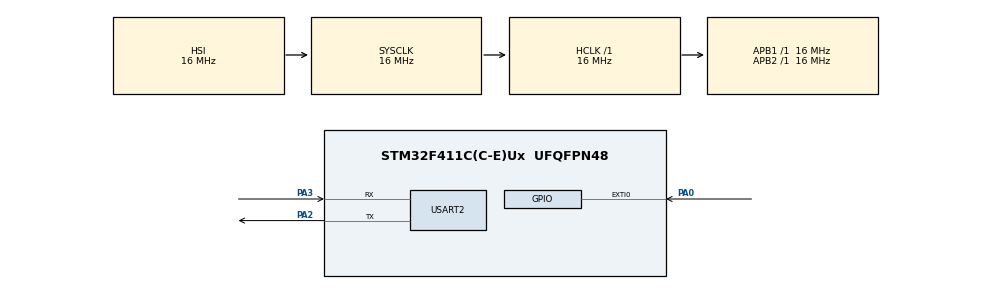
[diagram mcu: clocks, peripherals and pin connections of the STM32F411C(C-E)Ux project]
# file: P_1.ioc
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Mcu.Family=STM32F4
Mcu.Name=STM32F411C(C-E)Ux
Mcu.Package=UFQFPN48
NVIC.EXTI0_IRQn=true\:0\:0\:false\:false\:true\:true\:true\:true
NVIC.PriorityGroup=NVIC_PRIORITYGROUP_4
PA0-WKUP.GPIO_PuPd=GPIO_PULLUP
PA0-WKUP.Signal=GPXTI0
PA2.Mode=Asynchronous
PA2.Signal=USART2_TX
PA3.Mode=Asynchronous
PA3.Signal=USART2_RX
ProjectManager.HeapSize=0x200
ProjectManager.StackSize=0x400
ProjectManager.TargetToolchain=STM32CubeIDE
RCC.48MHZClocksFreq_Value=48000000
RCC.AHBFreq_Value=16000000
RCC.APB1Freq_Value=16000000
RCC.APB1TimFreq_Value=16000000
RCC.APB2Freq_Value=16000000
RCC.APB2TimFreq_Value=16000000
RCC.CortexFreq_Value=16000000
RCC.HCLKFreq_Value=16000000
RCC.HSE_VALUE=25000000
RCC.HSI_VALUE=16000000
RCC.LSE_VALUE=32768
RCC.PLLP=RCC_PLLP_DIV4
RCC.SYSCLKFreq_VALUE=16000000
RCC.VCOOutputFreq_Value=192000000
USART2.VirtualMode=VM_ASYNC
VP_CRC_VS_CRC.Mode=CRC_Activate
board=custom

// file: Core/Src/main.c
/* USER CODE BEGIN Header */
/**
  ******************************************************************************
  * @file           : main.c
  * @brief          : Main program body
  ******************************************************************************
  * @attention
  *
  * Copyright (c) 2025 STMicroelectronics.
  * All rights reserved.
  *
  * This software is licensed under terms that can be found in the LICENSE file
  * in the root directory of this software component.
  * If no LICENSE file comes with this software, it is provided AS-IS.
  *
  ******************************************************************************
  */
/* USER CODE END Header */
#include "main.h"

/* USER CODE BEGIN Includes */
#include <string.h>
#include <stdarg.h>
#include <stdio.h>
/* USER CODE END Includes */

CRC_HandleTypeDef hcrc;

UART_HandleTypeDef huart2;

/* USER CODE BEGIN PV */
#define C_UART			huart2

uint8_t bl_rx_buffer[200];
/* USER CODE END PV */

void SystemClock_Config(void);
static void MX_GPIO_Init(void);
static void MX_CRC_Init(void);
static void MX_USART2_UART_Init(void);
/* USER CODE BEGIN PFP */
static void printmsg(char *format,...);
static void bootloader_send_ack(uint8_t command_code, uint8_t follow_len);
static void bootloader_send_nack(void);
uint8_t bootloader_verify_crc (uint8_t *pData, uint32_t len, uint32_t crc_host);
static uint8_t get_bootloader_version(void);
static void bootloader_uart_write_data(uint8_t *pBuffer,uint32_t len);

/* USER CODE END PFP */

int main(void)
{

  /* USER CODE BEGIN 1 */
#define BL_DEBUG_MSG_EN		1
  /* USER CODE END 1 */

  /* MCU Configuration--------------------------------------------------------*/

  /* Reset of all peripherals, Initializes the Flash interface and the Systick. */
  HAL_Init();

  /* Configure the system clock */
  SystemClock_Config();

  /* Initialize all configured peripherals */
  MX_GPIO_Init();
  MX_CRC_Init();
  MX_USART2_UART_Init();
  /* USER CODE BEGIN 2 */

  if(HAL_GPIO_ReadPin(GPIOA, GPIO_PIN_0) == 0)
  {
	  // button is pressed
	  printmsg("BL_DEBUG_MSG:Button is pressed .. going to BL mode \r\n");

	  bootloader_uart_read_data();
  }
  else
  {
	printmsg("BL_DEBUG_MSG:Button is not pressed .. executing user app\r\n");
	 bootloader_jump_to_user_app();
  }

  /* USER CODE END 2 */

  /* Infinite loop */
  while (1)
  {

  }
}

void SystemClock_Config(void)
{
  RCC_OscInitTypeDef RCC_OscInitStruct = {0};
  RCC_ClkInitTypeDef RCC_ClkInitStruct = {0};

  /** Configure the main internal regulator output voltage
  */
  __HAL_RCC_PWR_CLK_ENABLE();
  __HAL_PWR_VOLTAGESCALING_CONFIG(PWR_REGULATOR_VOLTAGE_SCALE1);

  /** Initializes the RCC Oscillators according to the specified parameters
  * in the RCC_OscInitTypeDef structure.
  */
  RCC_OscInitStruct.OscillatorType = RCC_OSCILLATORTYPE_HSI;
  RCC_OscInitStruct.HSIState = RCC_HSI_ON;
  RCC_OscInitStruct.HSICalibrationValue = RCC_HSICALIBRATION_DEFAULT;
  RCC_OscInitStruct.PLL.PLLState = RCC_PLL_NONE;
  if (HAL_RCC_OscConfig(&RCC_OscInitStruct) != HAL_OK)
  {
    Error_Handler();
  }

  /** Initializes the CPU, AHB and APB buses clocks
  */
  RCC_ClkInitStruct.ClockType = RCC_CLOCKTYPE_HCLK|RCC_CLOCKTYPE_SYSCLK
                              |RCC_CLOCKTYPE_PCLK1|RCC_CLOCKTYPE_PCLK2;
  RCC_ClkInitStruct.SYSCLKSource = RCC_SYSCLKSOURCE_HSI;
  RCC_ClkInitStruct.AHBCLKDivider = RCC_SYSCLK_DIV1;
  RCC_ClkInitStruct.APB1CLKDivider = RCC_HCLK_DIV1;
  RCC_ClkInitStruct.APB2CLKDivider = RCC_HCLK_DIV1;

  if (HAL_RCC_ClockConfig(&RCC_ClkInitStruct, FLASH_LATENCY_0) != HAL_OK)
  {
    Error_Handler();
  }
}

static void MX_CRC_Init(void)
{

  hcrc.Instance = CRC;
  if (HAL_CRC_Init(&hcrc) != HAL_OK)
  {
    Error_Handler();
  }

}

static void MX_USART2_UART_Init(void)
{

  huart2.Instance = USART2;
  huart2.Init.BaudRate = 9600;
  huart2.Init.WordLength = UART_WORDLENGTH_8B;
  huart2.Init.StopBits = UART_STOPBITS_1;
  huart2.Init.Parity = UART_PARITY_NONE;
  huart2.Init.Mode = UART_MODE_TX_RX;
  huart2.Init.HwFlowCtl = UART_HWCONTROL_NONE;
  huart2.Init.OverSampling = UART_OVERSAMPLING_16;
  if (HAL_UART_Init(&huart2) != HAL_OK)
  {
    Error_Handler();
  }

}

static void MX_GPIO_Init(void)
{
  GPIO_InitTypeDef GPIO_InitStruct = {0};

  /* GPIO Ports Clock Enable */
  __HAL_RCC_GPIOA_CLK_ENABLE();

  /*Configure GPIO pin : PA0 */
  GPIO_InitStruct.Pin = GPIO_PIN_0;
  GPIO_InitStruct.Mode = GPIO_MODE_IT_RISING;
  GPIO_InitStruct.Pull = GPIO_PULLUP;
  HAL_GPIO_Init(GPIOA, &GPIO_InitStruct);

  /* EXTI interrupt init*/
  HAL_NVIC_SetPriority(EXTI0_IRQn, 0, 0);
  HAL_NVIC_EnableIRQ(EXTI0_IRQn);

}

/* USER CODE BEGIN 4 */
static void printmsg(char *format,...)
{
#ifdef BL_DEBUG_MSG_EN
	char str[80];

	va_list args;
	va_start(args, format);
	vsprintf(str, format, args);
	HAL_UART_Transmit(&huart2, (uint8_t*)str, strlen(str), HAL_MAX_DELAY);
	va_end(args);
#endif
}

void bootloader_uart_read_data(void)
{
	uint8_t rcv_len;
	memset(bl_rx_buffer, 0, 200);

	HAL_UART_Receive(&C_UART, bl_rx_buffer, 1, HAL_MAX_DELAY);
	rcv_len = bl_rx_buffer[0];
	HAL_UART_Receive(&C_UART, &bl_rx_buffer[1], rcv_len, HAL_MAX_DELAY);
	switch(bl_rx_buffer[1])
	{
		 case BL_GET_VER:
	          bootloader_handle_getver_cmd(bl_rx_buffer);
	          break;
	      case BL_GET_HELP:
	          bootloader_handle_gethelp_cmd(bl_rx_buffer);
	          break;
	      case BL_GET_CID:
	          bootloader_handle_getcid_cmd(bl_rx_buffer);
	          break;
	      case BL_GET_RDP_STATUS:
	          bootloader_handle_getrdp_cmd(bl_rx_buffer);
	          break;
	      case BL_GO_TO_ADDR:
	          bootloader_handle_go_cmd(bl_rx_buffer);
	          break;
	      case BL_FLASH_ERASE:
	          bootloader_handle_flash_erase_cmd(bl_rx_buffer);
	          break;
	      case BL_MEM_WRITE:
	          bootloader_handle_mem_write_cmd(bl_rx_buffer);
	          break;
	      case BL_EN_RW_PROTECT:
	          bootloader_handle_en_rw_protect(bl_rx_buffer);
	          break;
	      case BL_MEM_READ:
	          bootloader_handle_mem_read(bl_rx_buffer);
	          break;
	      case BL_READ_SECTOR_P_STATUS:
	          bootloader_handle_read_sector_protection_status(bl_rx_buffer);
	          break;
	      case BL_OTP_READ:
	          bootloader_handle_read_otp(bl_rx_buffer);
	          break;
	      case BL_DIS_R_W_PROTECT:
	          bootloader_handle_dis_rw_protect(bl_rx_buffer);
	          break;
	       default:
	          printmsg("BL_DEBUG_MSG:Invalid command code received from host \n");
	          break;
	}

}

void bootloader_jump_to_user_app(void)
{
	// function pointer to hold the address of the reset handler of the user app.
	void (*app_reset_handler) (void);

	printmsg("BL_DEBUG_MSG: bootloader_jump_to_user_app\n\r");

	//1. Configure the MSP by reading the value from the base address of the sector 2
	uint32_t msp_value = *(volatile uint32_t *)FLASH_SECTOR2_BASE_ADDRESS;
	printmsg("BL_DEBUS_MSG: MAP value: %#x\n\r", msp_value);

	//This function come from CMSIS
	__set_MSP(msp_value);

	//2. Now fetch the reset handler address of the user application
	uint32_t resethandler_address = *(volatile uint32_t *) (FLASH_SECTOR2_BASE_ADDRESS + 4);

	app_reset_handler = (void*) resethandler_address;
	printmsg("BL_DEBUG_MSG: app reset handler addr: %#x\n", app_reset_handler);

	//3. jump to reset handler of the user application
	app_reset_handler();

}

void HAL_GPIO_EXTI_Callback(uint16_t GPIO_Pin)
{
	printmsg("BL_DEBUG_MSG:Button is pressed .. going to BL mode \r\n");

}

void bootloader_handle_getver_cmd(uint8_t *bl_rx_buffer)
{
	uint8_t bl_version;
	//1. Verify the checksum(CRC)
	printmsg("BL_DEBUG_MSG:bootloader handler getver cmd\n");
	 // 1) verify the checksum
	  printmsg("BL_DEBUG_MSG:bootloader_handle_getver_cmd\n");

	  //Total length of the command packet
	  uint32_t command_packet_len = bl_rx_buffer[0]+1 ;

	  //extract the CRC32 sent by the Host
	  uint32_t host_crc = *((uint32_t * ) (bl_rx_buffer+command_packet_len - 4) ) ;

	if(! bootloader_verify_crc(&bl_rx_buffer[0], bl_rx_buffer[0]+1, 0))
	{
		printmsg("BL_DEBUG_MSG:checksum success !!\n");
		//checksum is correct..
		bootloader_send_ack(bl_rx_buffer[0],1);
		bl_version = get_bootloader_version();
		printmsg("BL_DEBUG_MSG:BL_VER: %d %#\n", bl_version, bl_version);
		bootloader_uart_write_data(&bl_version, 1);
	}else
	{
		printmsg("BL_DEBUS_MSG:checksum fail !!\n");
		//checksum is wrong send nack
		bootloader_send_nack();
	}

}
void bootloader_handle_gethelp_cmd(uint8_t *pBuffer)
{

}
void bootloader_handle_getcid_cmd(uint8_t *pBuffer)
{

}
void bootloader_handle_getrdp_cmd(uint8_t *pBuffer)
{

}
void bootloader_handle_go_cmd(uint8_t *pBuffer)
{

}
void bootloader_handle_flash_erase_cmd(uint8_t *pBuffer)
{

}
void bootloader_handle_mem_write_cmd(uint8_t *pBuffer)
{

}
void bootloader_handle_en_rw_protect(uint8_t *pBuffer)
{

}
void bootloader_handle_mem_read (uint8_t *pBuffer)
{

}
void bootloader_handle_read_sector_protection_status(uint8_t *pBuffer)
{

}
void bootloader_handle_read_otp(uint8_t *pBuffer)
{

}
void bootloader_handle_dis_rw_protect(uint8_t *pBuffer)
{

}

// helper funcitons
static void bootloader_send_ack(uint8_t command_code, uint8_t follow_len)
{
	//here we send 2 byte.. first byte is ack and the second bytes is len value
	uint8_t ack_buf[2];
	ack_buf[0] = BL_ACK;
	ack_buf[1] = follow_len;
	HAL_UART_Transmit(&C_UART, ack_buf, 2, HAL_MAX_DELAY);
}
static void bootloader_send_nack(void)
{
	uint8_t nack = BL_NACK;
	HAL_UART_Transmit(&C_UART, &nack, 1, HAL_MAX_DELAY);
}

static uint8_t get_bootloader_version(void)
{
	uint8_t ver = BL_VERSION;
	return ver;
}

uint8_t bootloader_verify_crc (uint8_t *pData, uint32_t len, uint32_t crc_host)
{

		uint32_t uwCRCValue=0xff;

		for (uint32_t i=0 ; i < len ; i++) {

		uint32_t i_data = pData[i];
		uwCRCValue = HAL_CRC_Accumulate(&hcrc, &i_data, 1);
		}

		/* Reset CRC Calculation Unit */
		__HAL_CRC_DR_RESET(&hcrc);

		if( uwCRCValue == crc_host) {

		return VERIFY_CRC_SUCCESS;
		}

		return VERIFY_CRC_FAIL;
}

static void bootloader_uart_write_data(uint8_t *pBuffer,uint32_t len) {

  /*you can replace the below ST's USART driver API call with your MCUs driver API call */
  HAL_UART_Transmit(&C_UART,pBuffer,len,HAL_MAX_DELAY);

}

/* USER CODE END 4 */

void Error_Handler(void)
{
  __disable_irq();
  while (1)
  {
  }
}
